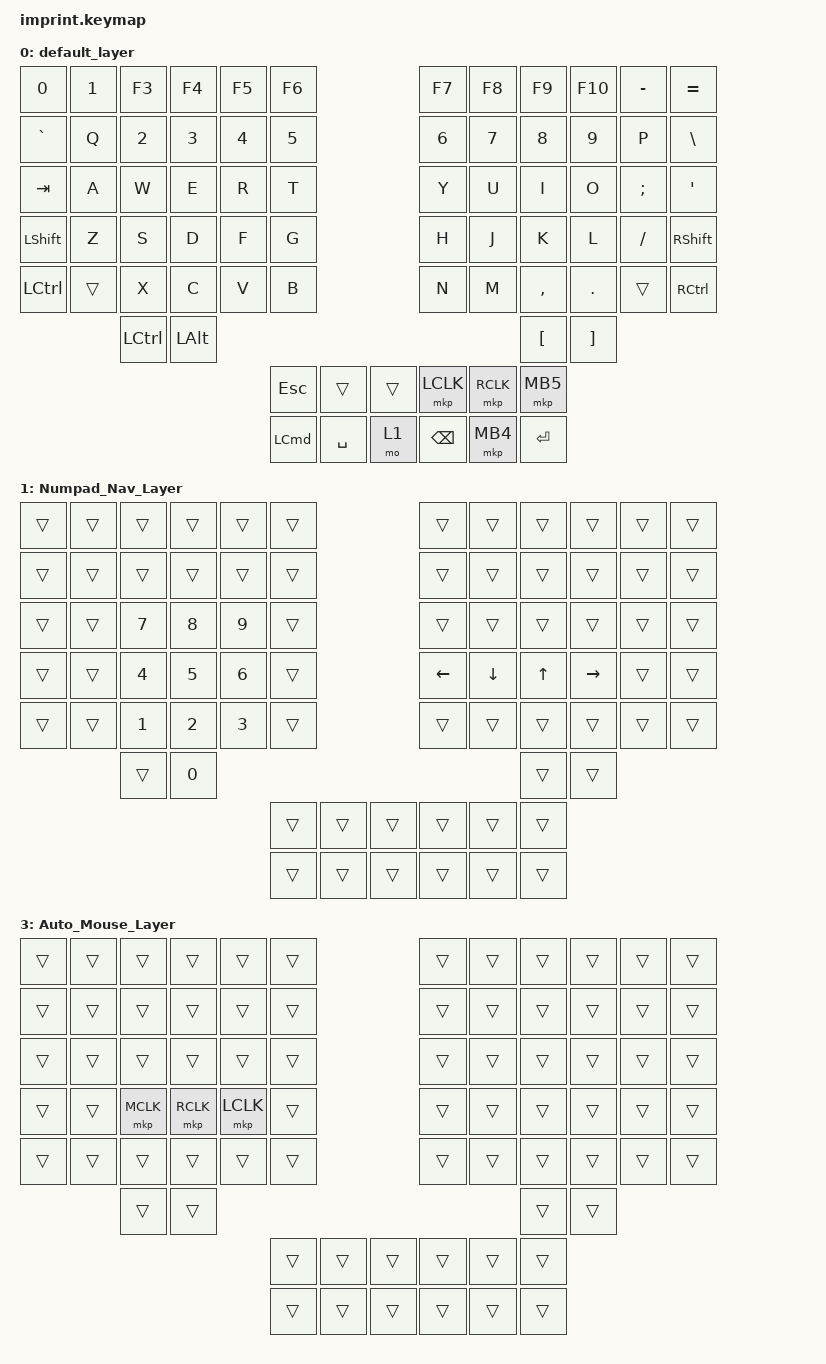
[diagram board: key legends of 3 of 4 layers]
#define PMW33XX_CPI 1200
#define ZMK_POINTING_DEFAULT_MOVE_VAL 1200
#define ZMK_POINTING_DEFAULT_SCRL_VAL 10

#include <input/processors.dtsi>
#include <dt-bindings/zmk/input_transform.h>
#include <behaviors.dtsi>
#include <dt-bindings/zmk/bt.h>
#include <dt-bindings/zmk/keys.h>
#include <dt-bindings/zmk/pointing.h>

/ {
    chosen { zmk,matrix-transform = &imprint_function_row;
    };
    
    // 添加鼠标行为配置
    behaviors {
        mmv: mouse_move {
            compatible = "zmk,behavior-input-two-axis";
            #binding-cells = <1>;
            x-input-code = <INPUT_REL_X>;
            y-input-code = <INPUT_REL_Y>;
            time-to-max-speed-ms = <200>; 
            acceleration-exponent = <1>; 
        };
    };
    
    keymap {
        compatible = "zmk,keymap";

        default_layer {
            bindings = <
 &kp N0     &kp N1    &kp F3    &kp F4    &kp F5  &kp F6                                         &kp F7      &kp F8     &kp F9    &kp F10  &kp MINUS   &kp EQUAL
 &kp GRAVE  &kp Q     &kp N2    &kp N3    &kp N4  &kp N5                                         &kp N6      &kp N7     &kp N8    &kp N9   &kp P       &kp BSLH
 &kp TAB    &kp A     &kp W     &kp E     &kp R   &kp T                                          &kp Y       &kp U      &kp I     &kp O    &kp SEMI    &kp SQT
 &kp LSHFT  &kp Z     &kp S     &kp D     &kp F   &kp G                                          &kp H       &kp J      &kp K     &kp L    &kp FSLH    &kp RSHFT
 &kp LCTRL  &trans    &kp X     &kp C     &kp V   &kp B                                          &kp N       &kp M      &kp COMMA &kp DOT  &trans      &kp RCTRL
                      &kp LCTRL &kp LALT                                                                                &kp LBKT  &kp RBKT
                                                  &kp ESC    &trans     &trans       &mkp LCLK  &mkp RCLK   &mkp MB5   
                                                  &kp LCMD   &kp SPACE  &mo 1        &kp  BSPC  &mkp MB4    &kp ENTER
            >;
        };

        Numpad_Nav_Layer {
            bindings = <
 &trans  &trans  &trans  &trans  &trans  &trans                                     &trans    &trans    &trans    &trans     &trans     &trans
 &trans  &trans  &trans  &trans  &trans  &trans                                     &trans    &trans    &trans    &trans     &trans     &trans
 &trans  &trans  &kp N7  &kp N8  &kp N9  &trans                                     &trans    &trans    &trans    &trans     &trans     &trans
 &trans  &trans  &kp N4  &kp N5  &kp N6  &trans                                     &kp LEFT  &kp DOWN  &kp UP    &kp RIGHT  &trans     &trans
 &trans  &trans  &kp N1  &kp N2  &kp N3  &trans                                     &trans    &trans    &trans    &trans     &trans     &trans
                 &trans  &kp N0                                                                         &trans    &trans
                                      &trans  &trans &trans       &trans  &trans &trans
                                      &trans  &trans &trans       &trans  &trans &trans
            >;
        };

        Keyboard_Control_Layer {
            bindings = <
&trans       &trans        &trans        &trans        &trans        &trans                  &trans  &trans           &trans           &trans           &trans           &trans
&bt BT_CLR   &bt BT_SEL 0  &bt BT_SEL 1  &bt BT_SEL 2  &bt BT_SEL 3  &bt BT_SEL 4            &trans  &trans           &trans           &trans           &trans           &trans
&sys_reset   &trans        &trans        &trans        &trans        &trans                  &trans  &trans           &trans           &trans           &trans           &trans
&bootloader  &trans        &trans        &trans        &trans        &trans                  &trans  &trans           &trans           &trans           &trans           &trans
&to 4        &trans        &trans        &trans        &trans        &trans                  &trans  &trans           &trans           &trans           &trans           &to 4
&to 4        &trans        &trans        &trans        &trans                                        &trans           &trans           &trans           &trans           &to 4
                                                       &trans        &trans        &trans    &trans  &trans           &trans
                                                       &trans        &trans        &trans    &trans  &trans           &trans
            >;
        };

        Auto_Mouse_Layer {
            bindings = <
 &trans  &trans  &trans  &trans  &trans  &trans                                     &trans  &trans  &trans  &trans  &trans  &trans
 &trans  &trans  &trans  &trans  &trans  &trans                                     &trans  &trans  &trans  &trans  &trans  &trans
 &trans  &trans  &trans  &trans  &trans  &trans                                     &trans  &trans  &trans  &trans  &trans  &trans
 &trans  &trans  &mkp MCLK  &mkp RCLK &mkp LCLK &trans                              &trans  &trans  &trans  &trans  &trans  &trans
 &trans  &trans  &trans  &trans  &trans  &trans                                     &trans  &trans  &trans  &trans  &trans  &trans
                 &trans  &trans                                                                     &trans  &trans
                                         &trans  &trans &trans        &trans &trans &trans
                                         &trans  &trans &trans        &trans &trans &trans
            >;
        };
    };
};

//right hand trackball configuration
&trackball_peripheral_listener {
    compatible = "zmk,input-listener";
    scroll {
        layers = <1>;
        input-processors =
            <&zip_xy_scaler 1 25>,
            <&zip_xy_to_scroll_mapper>,
            <&zip_scroll_transform INPUT_TRANSFORM_Y_INVERT>;
    };
};
